# PIC32CM2532JH00100 register map
Vendor: Microchip Technology; Series: PIC32CMJH00; File version: 0
CPU: CM0+ r0p0, little endian, MPU, no FPU, VTOR, 2 interrupt priority bits, 32 interrupts
Registers are 32-bit, read-write, reset 0x0 unless marked. A register's access mark holds for its fields unless they carry their own. Offsets are from the block's base; [hi:lo] are bit positions; {n}, {i} and the like mark numbered series.

## PAC — Peripheral Access Controller
Base 0x40000000
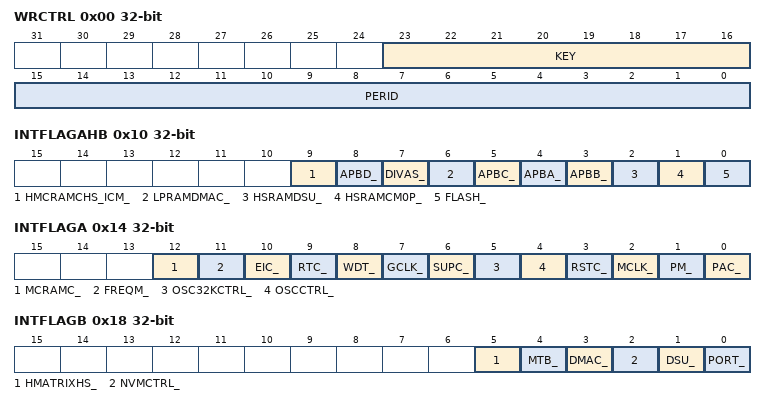
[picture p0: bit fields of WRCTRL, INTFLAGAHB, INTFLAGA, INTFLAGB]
0x00 WRCTRL — Write control
  [23:16] KEY — Peripheral access control key
    0=OFF (No action); 1=CLR (Clear protection); 2=SET (Set protection); 3=SETLCK (Set and lock protection)
  [15:0] PERID — Peripheral identifier
0x04 EVCTRL 8-bit — Event control
  [0] ERREO — Peripheral acess error event output
0x08 INTENCLR 8-bit write-1-clears — Interrupt enable clear
  [0] ERR — Peripheral access error interrupt disable
0x09 INTENSET 8-bit write-1-sets — Interrupt enable set
  [0] ERR — Peripheral access error interrupt enable
0x10 INTFLAGAHB write-1-clears — Bridge interrupt flag status
  [9] HMCRAMCHS_ICM_ — SRAM ICM
  [8] APBD_ — HPB3
  [7] DIVAS_
  [6] LPRAMDMAC_ — SRAM DMAC
  [5] APBC_ — HPB2
  [4] APBA_ — HPB0
  [3] APBB_ — HPB1
  [2] HSRAMDSU_ — SRAM DSU
  [1] HSRAMCM0P_ — SRAM CPU
  [0] FLASH_
0x14 INTFLAGA write-1-clears — Peripheral interrupt flag status - Bridge A
  [12] MCRAMC_, [11] FREQM_, [10] EIC_, [9] RTC_, [8] WDT_, [7] GCLK_, [6] SUPC_, [5] OSC32KCTRL_, [4] OSCCTRL_, [3] RSTC_, [2] MCLK_, [1] PM_, [0] PAC_
0x18 INTFLAGB write-1-clears — Peripheral interrupt flag status - Bridge B
  [5] HMATRIXHS_, [4] MTB_, [3] DMAC_, [2] NVMCTRL_, [1] DSU_, [0] PORT_
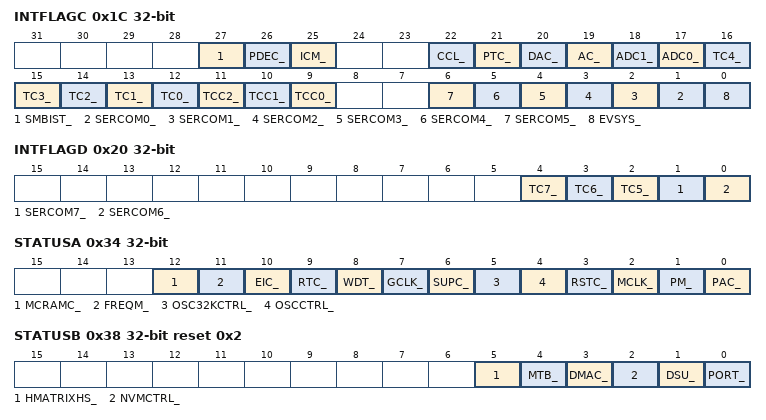
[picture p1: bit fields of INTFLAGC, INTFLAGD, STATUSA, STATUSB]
0x1C INTFLAGC write-1-clears — Peripheral interrupt flag status - Bridge C
  [27] SMBIST_, [26] PDEC_, [25] ICM_, [22] CCL_, [21] PTC_, [20] DAC_, [19] AC_, [18] ADC1_, [17] ADC0_, [n+12] TC{n}_ (n=0..4), [11] TCC2_, [10] TCC1_, [9] TCC0_, [n+1] SERCOM{n}_ (n=0..5), [0] EVSYS_
0x20 INTFLAGD write-1-clears — Peripheral interrupt flag status - Bridge D
  [4] TC7_, [3] TC6_, [2] TC5_, [1] SERCOM7_, [0] SERCOM6_
0x34 STATUSA ro — Peripheral write protection status - Bridge A
  [12] MCRAMC_ — MCRAMC APB Protect Enable
  [11] FREQM_ — FREQM APB Protect Enable
  [10] EIC_ — EIC APB Protect Enable
  [9] RTC_ — RTC APB Protect Enable
  [8] WDT_ — WDT APB Protect Enable
  [7] GCLK_ — GCLK APB Protect Enable
  [6] SUPC_ — SUPC APB Protect Enable
  [5] OSC32KCTRL_ — OSC32KCTRL APB Protect Enable
  [4] OSCCTRL_ — OSCCTRL APB Protect Enable
  [3] RSTC_ — RSTC APB Protect Enable
  [2] MCLK_ — MCLK APB Protect Enable
  [1] PM_ — PM APB Protect Enable
  [0] PAC_ — PAC APB Protect Enable
0x38 STATUSB ro reset 0x2 — Peripheral write protection status - Bridge B
  [5] HMATRIXHS_ — HMATRIXHS APB Protect Enable
  [4] MTB_ — MTB APB Protect Enable
  [3] DMAC_ — DMAC APB Protect Enable
  [2] NVMCTRL_ — NVMCTRL APB Protect Enable
  [1] DSU_ — DSU APB Protect Enable
  [0] PORT_ — PORT APB Protect Enable
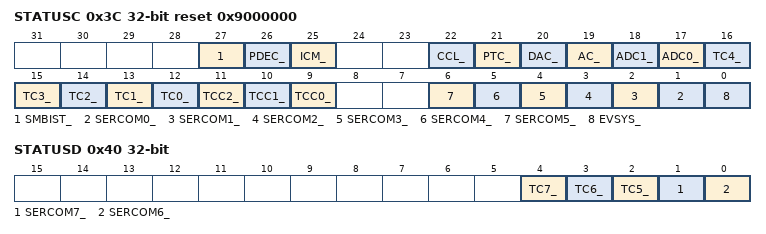
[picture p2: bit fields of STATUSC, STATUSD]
0x3C STATUSC ro reset 0x9000000 — Peripheral write protection status - Bridge C
  [27] SMBIST_ — SMBIST APB Protect Enable
  [26] PDEC_ — PDEC APB Protect Enable
  [25] ICM_ — ICM APB Protect Enable
  [22] CCL_ — CCL APB Protect Enable
  [21] PTC_ — PTC APB Protect Enable
  [20] DAC_ — DAC APB Protect Enable
  [19] AC_ — AC APB Protect Enable
  [18] ADC1_ — ADC1 APB Protect Enable
  [17] ADC0_ — ADC0 APB Protect Enable
  [n+12] TC{n}_ (n=0..4) — TC{n} APB Protect Enable
  [11] TCC2_ — TCC2 APB Protect Enable
  [10] TCC1_ — TCC1 APB Protect Enable
  [9] TCC0_ — TCC0 APB Protect Enable
  [n+1] SERCOM{n}_ (n=0..5) — SERCOM{n} APB Protect Enable
  [0] EVSYS_ — EVSYS APB Protect Enable
0x40 STATUSD ro — Peripheral write protection status - Bridge D
  [4] TC7_ — TC7 APB Protect Enable
  [3] TC6_ — TC6 APB Protect Enable
  [2] TC5_ — TC5 APB Protect Enable
  [1] SERCOM7_ — SERCOM7 APB Protect Enable
  [0] SERCOM6_ — SERCOM6 APB Protect Enable

## PM — Power Manager
Base 0x40000400
0x01 SLEEPCFG 8-bit — Sleep Configuration
  [2:0] SLEEPMODE
    0=IDLE0 (CPU clock is OFF. AHB/APB clocks are provided to CAN and to IPs requesting them); 2=IDLE2 (CPU clock is OFF. AHB/APB clocks are provided to IPs requesting them (CAN excluded)); 4=STANDBY (CPU clock is OFF. AHB/APB clocks are stopped except if requested)
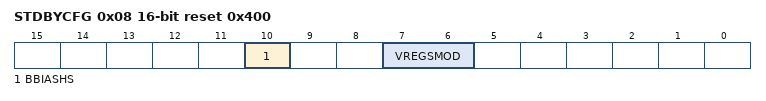
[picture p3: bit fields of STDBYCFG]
0x08 STDBYCFG 16-bit reset 0x400 — Standby Configuration
  [10] BBIASHS — Back Bias for SRAM
  [7:6] VREGSMOD — Voltage Regulator Standby mode
    0=AUTO (Automatic mode); 1=PERFORMANCE (Performance oriented); 2=LP (Low Power oriented)
